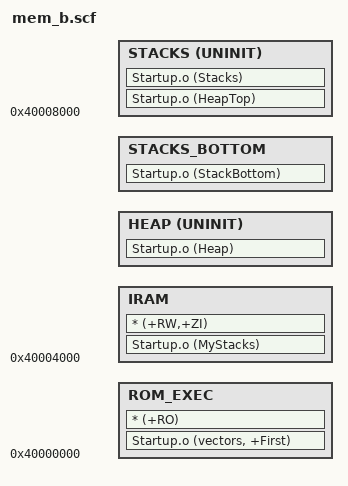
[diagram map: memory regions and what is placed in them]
;/****************************************Copyright (c)**************************************************
;**                               Guangzou ZLG-MCU Development Co.,LTD.
;**                                      graduate school
;**                                 http://www.zlgmcu.com
;**
;**--------------File Info-------------------------------------------------------------------------------
;** File Name: men_b.scf
;** Last modified Date:  2004-09-17
;** Last Version: 1.0
;** Descriptions: Scatter File
;**
;**------------------------------------------------------------------------------------------------------
;** Created By: Chenmingji
;** Created date:   2004-09-17
;** Version: 1.0
;** Descriptions: First version
;**
;**------------------------------------------------------------------------------------------------------
;** Modified by: zhangrijin
;** Modified date: 2007-01-09
;** Version:
;** Descriptions:   
;**
;********************************************************************************************************/
ROM_LOAD 0x40000000
{
    ROM_EXEC 0x40000000
    {
        Startup.o (vectors, +First)
        * (+RO)
    }
    IRAM 0x40004000    ;for LPC2366/68/78
    ;IRAM 0x40001000     ;for LPC2364
    {
        Startup.o (MyStacks)
        * (+RW,+ZI)
    }

    HEAP +0 UNINIT
    {
        Startup.o (Heap)
    }

    STACKS_BOTTOM +0
    {
        Startup.o (StackBottom)
    }

    STACKS 0x40008000 UNINIT    ;for LPC2366/68/78
;    STACKS 0x40002000 UNINIT    ;for LPC2364
    {
        Startup.o (HeapTop)
        Startup.o (Stacks)
    }
}

